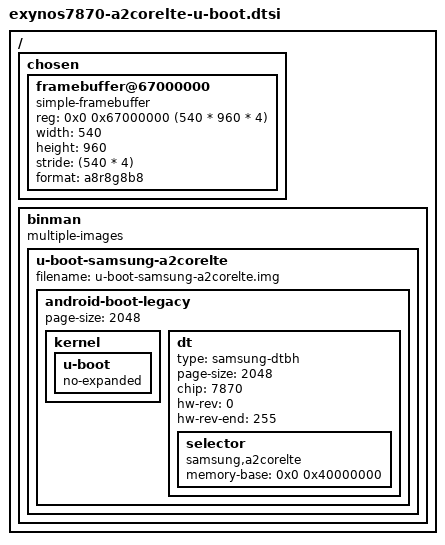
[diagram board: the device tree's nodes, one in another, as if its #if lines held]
// SPDX-License-Identifier: GPL-2.0
/*
 * Copyright (c) 2026 Kaustabh Chakraborty <kauschluss@disroot.org>
 */

#include <config.h>

/ {
	chosen {
		#address-cells = <2>;
		#size-cells = <1>;
		ranges;

		framebuffer@67000000 {
			compatible = "simple-framebuffer";
			reg = <0x0 0x67000000 (540 * 960 * 4)>;
			width = <540>;
			height = <960>;
			stride = <(540 * 4)>;
			format = "a8r8g8b8";
		};
	};
};

#ifdef CONFIG_SAMSUNG_EXYNOS_LEGACY_BOOT_IMAGE
/ {
	binman: binman {
		multiple-images;

		u-boot-samsung-a2corelte {
			filename = "u-boot-samsung-a2corelte.img";

			android-boot-legacy {
				page-size = <2048>;

				kernel {
					u-boot {
						no-expanded;
					};
				};

				dt {
					type = "samsung-dtbh";
					page-size = <2048>;
					chip = <7870>;
					hw-rev = <0>;
					hw-rev-end = <255>;

					selector {
						compatible = "samsung,a2corelte",
							     "samsung,exynos7870";
						memory-base = <0x0 0x40000000>;
					};
				};
			};
		};
	};
};
#endif
